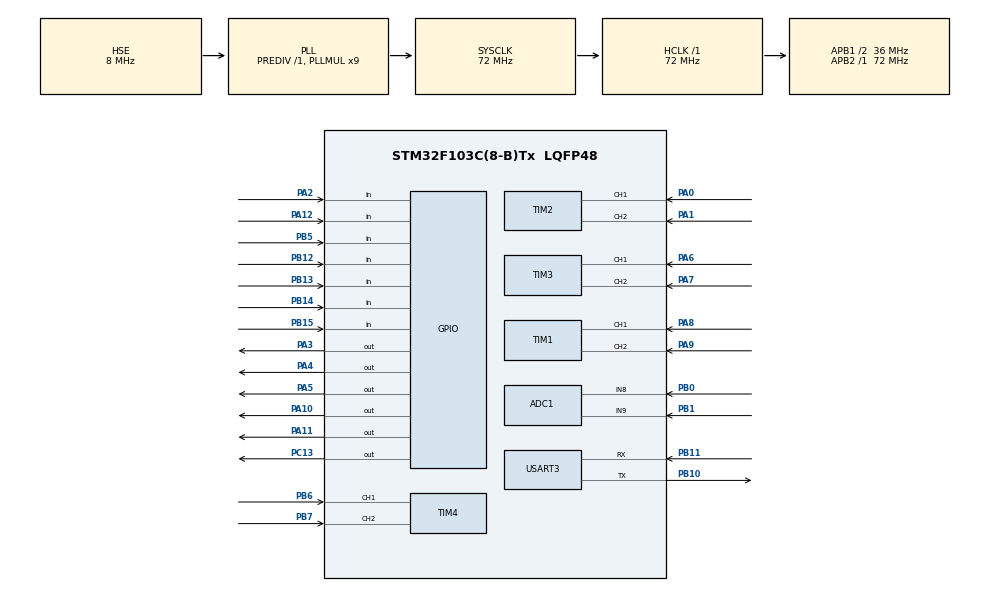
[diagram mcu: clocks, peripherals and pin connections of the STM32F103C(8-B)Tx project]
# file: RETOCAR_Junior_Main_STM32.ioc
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ADC1.Channel-2\#ChannelRegularConversion=ADC_CHANNEL_8
ADC1.NbrOfConversionFlag=1
ADC1.Rank-2\#ChannelRegularConversion=1
ADC1.SamplingTime-2\#ChannelRegularConversion=ADC_SAMPLETIME_239CYCLES_5
ADC1.master=1
Dma.Request0=USART3_RX
Dma.Request1=USART3_TX
Dma.USART3_RX.0.Direction=DMA_PERIPH_TO_MEMORY
Dma.USART3_RX.0.Instance=DMA1_Channel3
Dma.USART3_RX.0.MemDataAlignment=DMA_MDATAALIGN_BYTE
Dma.USART3_RX.0.MemInc=DMA_MINC_ENABLE
Dma.USART3_RX.0.Mode=DMA_CIRCULAR
Dma.USART3_RX.0.PeriphDataAlignment=DMA_PDATAALIGN_BYTE
Dma.USART3_RX.0.PeriphInc=DMA_PINC_DISABLE
Dma.USART3_RX.0.Priority=DMA_PRIORITY_LOW
Dma.USART3_TX.1.Direction=DMA_MEMORY_TO_PERIPH
Dma.USART3_TX.1.Instance=DMA1_Channel2
Dma.USART3_TX.1.MemDataAlignment=DMA_MDATAALIGN_BYTE
Dma.USART3_TX.1.MemInc=DMA_MINC_ENABLE
Dma.USART3_TX.1.Mode=DMA_NORMAL
Dma.USART3_TX.1.PeriphDataAlignment=DMA_PDATAALIGN_BYTE
Dma.USART3_TX.1.PeriphInc=DMA_PINC_DISABLE
Dma.USART3_TX.1.Priority=DMA_PRIORITY_LOW
Mcu.Family=STM32F1
Mcu.Name=STM32F103C(8-B)Tx
Mcu.Package=LQFP48
NVIC.DMA1_Channel2_IRQn=true\:0\:0\:false\:false\:true\:false\:true\:true
NVIC.DMA1_Channel3_IRQn=true\:0\:0\:false\:false\:true\:false\:true\:true
NVIC.PriorityGroup=NVIC_PRIORITYGROUP_4
NVIC.USART3_IRQn=true\:0\:0\:false\:false\:true\:true\:true\:true
PA0-WKUP.Signal=S_TIM2_CH1_ETR
PA1.Signal=S_TIM2_CH2
PA10.Signal=GPIO_Output
PA11.Signal=GPIO_Output
PA12.Signal=GPIO_Input
PA13.Mode=Serial_Wire
PA13.Signal=SYS_JTMS-SWDIO
PA14.Mode=Serial_Wire
PA14.Signal=SYS_JTCK-SWCLK
PA2.Signal=GPIO_Input
PA3.Signal=GPIO_Output
PA4.Signal=GPIO_Output
PA5.Signal=GPIO_Output
PA6.Signal=S_TIM3_CH1
PA7.Signal=S_TIM3_CH2
PA8.Signal=S_TIM1_CH1
PA9.Signal=S_TIM1_CH2
PB0.Signal=ADCx_IN8
PB1.Signal=ADCx_IN9
PB10.Mode=Asynchronous
PB10.Signal=USART3_TX
PB11.Mode=Asynchronous
PB11.Signal=USART3_RX
PB12.Signal=GPIO_Input
PB13.Signal=GPIO_Input
PB14.Signal=GPIO_Input
PB15.Signal=GPIO_Input
PB5.Signal=GPIO_Input
PB6.Signal=S_TIM4_CH1
PB7.Signal=S_TIM4_CH2
PC13-TAMPER-RTC.Signal=GPIO_Output
PD0-OSC_IN.Mode=HSE-External-Oscillator
PD0-OSC_IN.Signal=RCC_OSC_IN
PD1-OSC_OUT.Mode=HSE-External-Oscillator
PD1-OSC_OUT.Signal=RCC_OSC_OUT
ProjectManager.HeapSize=0x200
ProjectManager.StackSize=0x400
ProjectManager.TargetToolchain=STM32CubeIDE
RCC.AHBFreq_Value=72000000
RCC.APB1CLKDivider=RCC_HCLK_DIV2
RCC.APB1Freq_Value=36000000
RCC.APB1TimFreq_Value=72000000
RCC.APB2Freq_Value=72000000
RCC.APB2TimFreq_Value=72000000
RCC.EnbaleCSS=true
RCC.HCLKFreq_Value=72000000
RCC.PLLMUL=RCC_PLL_MUL9
RCC.PLLSourceVirtual=RCC_PLLSOURCE_HSE
RCC.SYSCLKFreq_VALUE=72000000
RCC.SYSCLKSource=RCC_SYSCLKSOURCE_PLLCLK
RCC.USBFreq_Value=72000000
SH.ADCx_IN8.0=ADC1_IN8,IN8
SH.ADCx_IN9.0=ADC1_IN9,IN9
SH.S_TIM1_CH1.0=TIM1_CH1,Encoder_Interface
SH.S_TIM1_CH2.0=TIM1_CH2,Encoder_Interface
SH.S_TIM2_CH1_ETR.0=TIM2_CH1,Encoder_Interface
SH.S_TIM2_CH2.0=TIM2_CH2,Encoder_Interface
SH.S_TIM3_CH1.0=TIM3_CH1,Encoder_Interface
SH.S_TIM3_CH2.0=TIM3_CH2,Encoder_Interface
SH.S_TIM4_CH1.0=TIM4_CH1,Encoder_Interface
SH.S_TIM4_CH2.0=TIM4_CH2,Encoder_Interface
TIM1.EncoderMode=TIM_ENCODERMODE_TI12
TIM1.IC1Filter=15
TIM1.IC2Filter=15
TIM2.EncoderMode=TIM_ENCODERMODE_TI12
TIM2.IC1Filter=15
TIM2.IC2Filter=15
TIM3.EncoderMode=TIM_ENCODERMODE_TI12
TIM3.IC1Filter=15
TIM3.IC2Filter=15
TIM4.EncoderMode=TIM_ENCODERMODE_TI12
TIM4.IC1Filter=15
TIM4.IC2Filter=15
USART3.VirtualMode=VM_ASYNC
board=custom

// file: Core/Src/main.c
/* USER CODE BEGIN Header */
/**
  ******************************************************************************
  * @file           : main.c
  * @brief          : Main program body
  ******************************************************************************
  * @attention
  *
  * Copyright (c) 2026 STMicroelectronics.
  * All rights reserved.
  *
  * This software is licensed under terms that can be found in the LICENSE file
  * in the root directory of this software component.
  * If no LICENSE file comes with this software, it is provided AS-IS.
  *
  ******************************************************************************
  */
/* USER CODE END Header */
#include "main.h"

/* USER CODE BEGIN Includes */
#include "../lib/Application.hpp"
/* USER CODE END Includes */

ADC_HandleTypeDef hadc1;

TIM_HandleTypeDef htim1;
TIM_HandleTypeDef htim2;
TIM_HandleTypeDef htim3;
TIM_HandleTypeDef htim4;

UART_HandleTypeDef huart3;
DMA_HandleTypeDef hdma_usart3_rx;
DMA_HandleTypeDef hdma_usart3_tx;

void SystemClock_Config(void);
static void MX_GPIO_Init(void);
static void MX_DMA_Init(void);
static void MX_TIM1_Init(void);
static void MX_TIM2_Init(void);
static void MX_TIM3_Init(void);
static void MX_TIM4_Init(void);
static void MX_USART3_UART_Init(void);
static void MX_ADC1_Init(void);

int main(void)
{

  /* MCU Configuration--------------------------------------------------------*/

  /* Reset of all peripherals, Initializes the Flash interface and the Systick. */
  HAL_Init();

  /* Configure the system clock */
  SystemClock_Config();

  /* Initialize all configured peripherals */
  MX_GPIO_Init();
  MX_DMA_Init();
  MX_TIM1_Init();
  MX_TIM2_Init();
  MX_TIM3_Init();
  MX_TIM4_Init();
  MX_USART3_UART_Init();
  MX_ADC1_Init();
  /* USER CODE BEGIN 2 */
  AppMain_Init();
  /* USER CODE END 2 */

  /* Infinite loop */
  while (1)
  {

    /* USER CODE BEGIN 3 */
    AppMain_Loop();
    HAL_Delay(10);
  }
  /* USER CODE END 3 */
}

void SystemClock_Config(void)
{
  RCC_OscInitTypeDef RCC_OscInitStruct = {0};
  RCC_ClkInitTypeDef RCC_ClkInitStruct = {0};
  RCC_PeriphCLKInitTypeDef PeriphClkInit = {0};

  /** Initializes the RCC Oscillators according to the specified parameters
  * in the RCC_OscInitTypeDef structure.
  */
  RCC_OscInitStruct.OscillatorType = RCC_OSCILLATORTYPE_HSE;
  RCC_OscInitStruct.HSEState = RCC_HSE_ON;
  RCC_OscInitStruct.HSEPredivValue = RCC_HSE_PREDIV_DIV1;
  RCC_OscInitStruct.HSIState = RCC_HSI_ON;
  RCC_OscInitStruct.PLL.PLLState = RCC_PLL_ON;
  RCC_OscInitStruct.PLL.PLLSource = RCC_PLLSOURCE_HSE;
  RCC_OscInitStruct.PLL.PLLMUL = RCC_PLL_MUL9;
  if (HAL_RCC_OscConfig(&RCC_OscInitStruct) != HAL_OK)
  {
    Error_Handler();
  }

  /** Initializes the CPU, AHB and APB buses clocks
  */
  RCC_ClkInitStruct.ClockType = RCC_CLOCKTYPE_HCLK|RCC_CLOCKTYPE_SYSCLK
                              |RCC_CLOCKTYPE_PCLK1|RCC_CLOCKTYPE_PCLK2;
  RCC_ClkInitStruct.SYSCLKSource = RCC_SYSCLKSOURCE_PLLCLK;
  RCC_ClkInitStruct.AHBCLKDivider = RCC_SYSCLK_DIV1;
  RCC_ClkInitStruct.APB1CLKDivider = RCC_HCLK_DIV2;
  RCC_ClkInitStruct.APB2CLKDivider = RCC_HCLK_DIV1;

  if (HAL_RCC_ClockConfig(&RCC_ClkInitStruct, FLASH_LATENCY_2) != HAL_OK)
  {
    Error_Handler();
  }
  PeriphClkInit.PeriphClockSelection = RCC_PERIPHCLK_ADC;
  PeriphClkInit.AdcClockSelection = RCC_ADCPCLK2_DIV2;
  if (HAL_RCCEx_PeriphCLKConfig(&PeriphClkInit) != HAL_OK)
  {
    Error_Handler();
  }

  /** Enables the Clock Security System
  */
  HAL_RCC_EnableCSS();
}

static void MX_ADC1_Init(void)
{

  ADC_ChannelConfTypeDef sConfig = {0};

  /** Common config
  */
  hadc1.Instance = ADC1;
  hadc1.Init.ScanConvMode = ADC_SCAN_DISABLE;
  hadc1.Init.ContinuousConvMode = DISABLE;
  hadc1.Init.DiscontinuousConvMode = DISABLE;
  hadc1.Init.ExternalTrigConv = ADC_SOFTWARE_START;
  hadc1.Init.DataAlign = ADC_DATAALIGN_RIGHT;
  hadc1.Init.NbrOfConversion = 1;
  if (HAL_ADC_Init(&hadc1) != HAL_OK)
  {
    Error_Handler();
  }

  /** Configure Regular Channel
  */
  sConfig.Channel = ADC_CHANNEL_8;
  sConfig.Rank = ADC_REGULAR_RANK_1;
  sConfig.SamplingTime = ADC_SAMPLETIME_239CYCLES_5;
  if (HAL_ADC_ConfigChannel(&hadc1, &sConfig) != HAL_OK)
  {
    Error_Handler();
  }

}

static void MX_TIM1_Init(void)
{

  TIM_Encoder_InitTypeDef sConfig = {0};
  TIM_MasterConfigTypeDef sMasterConfig = {0};

  htim1.Instance = TIM1;
  htim1.Init.Prescaler = 0;
  htim1.Init.CounterMode = TIM_COUNTERMODE_UP;
  htim1.Init.Period = 65535;
  htim1.Init.ClockDivision = TIM_CLOCKDIVISION_DIV1;
  htim1.Init.RepetitionCounter = 0;
  htim1.Init.AutoReloadPreload = TIM_AUTORELOAD_PRELOAD_DISABLE;
  sConfig.EncoderMode = TIM_ENCODERMODE_TI12;
  sConfig.IC1Polarity = TIM_ICPOLARITY_RISING;
  sConfig.IC1Selection = TIM_ICSELECTION_DIRECTTI;
  sConfig.IC1Prescaler = TIM_ICPSC_DIV1;
  sConfig.IC1Filter = 15;
  sConfig.IC2Polarity = TIM_ICPOLARITY_RISING;
  sConfig.IC2Selection = TIM_ICSELECTION_DIRECTTI;
  sConfig.IC2Prescaler = TIM_ICPSC_DIV1;
  sConfig.IC2Filter = 15;
  if (HAL_TIM_Encoder_Init(&htim1, &sConfig) != HAL_OK)
  {
    Error_Handler();
  }
  sMasterConfig.MasterOutputTrigger = TIM_TRGO_RESET;
  sMasterConfig.MasterSlaveMode = TIM_MASTERSLAVEMODE_DISABLE;
  if (HAL_TIMEx_MasterConfigSynchronization(&htim1, &sMasterConfig) != HAL_OK)
  {
    Error_Handler();
  }

}

static void MX_TIM2_Init(void)
{

  TIM_Encoder_InitTypeDef sConfig = {0};
  TIM_MasterConfigTypeDef sMasterConfig = {0};

  htim2.Instance = TIM2;
  htim2.Init.Prescaler = 0;
  htim2.Init.CounterMode = TIM_COUNTERMODE_UP;
  htim2.Init.Period = 65535;
  htim2.Init.ClockDivision = TIM_CLOCKDIVISION_DIV1;
  htim2.Init.AutoReloadPreload = TIM_AUTORELOAD_PRELOAD_DISABLE;
  sConfig.EncoderMode = TIM_ENCODERMODE_TI12;
  sConfig.IC1Polarity = TIM_ICPOLARITY_RISING;
  sConfig.IC1Selection = TIM_ICSELECTION_DIRECTTI;
  sConfig.IC1Prescaler = TIM_ICPSC_DIV1;
  sConfig.IC1Filter = 15;
  sConfig.IC2Polarity = TIM_ICPOLARITY_RISING;
  sConfig.IC2Selection = TIM_ICSELECTION_DIRECTTI;
  sConfig.IC2Prescaler = TIM_ICPSC_DIV1;
  sConfig.IC2Filter = 15;
  if (HAL_TIM_Encoder_Init(&htim2, &sConfig) != HAL_OK)
  {
    Error_Handler();
  }
  sMasterConfig.MasterOutputTrigger = TIM_TRGO_RESET;
  sMasterConfig.MasterSlaveMode = TIM_MASTERSLAVEMODE_DISABLE;
  if (HAL_TIMEx_MasterConfigSynchronization(&htim2, &sMasterConfig) != HAL_OK)
  {
    Error_Handler();
  }

}

static void MX_TIM3_Init(void)
{

  TIM_Encoder_InitTypeDef sConfig = {0};
  TIM_MasterConfigTypeDef sMasterConfig = {0};

  htim3.Instance = TIM3;
  htim3.Init.Prescaler = 0;
  htim3.Init.CounterMode = TIM_COUNTERMODE_UP;
  htim3.Init.Period = 65535;
  htim3.Init.ClockDivision = TIM_CLOCKDIVISION_DIV1;
  htim3.Init.AutoReloadPreload = TIM_AUTORELOAD_PRELOAD_DISABLE;
  sConfig.EncoderMode = TIM_ENCODERMODE_TI12;
  sConfig.IC1Polarity = TIM_ICPOLARITY_RISING;
  sConfig.IC1Selection = TIM_ICSELECTION_DIRECTTI;
  sConfig.IC1Prescaler = TIM_ICPSC_DIV1;
  sConfig.IC1Filter = 15;
  sConfig.IC2Polarity = TIM_ICPOLARITY_RISING;
  sConfig.IC2Selection = TIM_ICSELECTION_DIRECTTI;
  sConfig.IC2Prescaler = TIM_ICPSC_DIV1;
  sConfig.IC2Filter = 15;
  if (HAL_TIM_Encoder_Init(&htim3, &sConfig) != HAL_OK)
  {
    Error_Handler();
  }
  sMasterConfig.MasterOutputTrigger = TIM_TRGO_RESET;
  sMasterConfig.MasterSlaveMode = TIM_MASTERSLAVEMODE_DISABLE;
  if (HAL_TIMEx_MasterConfigSynchronization(&htim3, &sMasterConfig) != HAL_OK)
  {
    Error_Handler();
  }

}

static void MX_TIM4_Init(void)
{

  TIM_Encoder_InitTypeDef sConfig = {0};
  TIM_MasterConfigTypeDef sMasterConfig = {0};

  htim4.Instance = TIM4;
  htim4.Init.Prescaler = 0;
  htim4.Init.CounterMode = TIM_COUNTERMODE_UP;
  htim4.Init.Period = 65535;
  htim4.Init.ClockDivision = TIM_CLOCKDIVISION_DIV1;
  htim4.Init.AutoReloadPreload = TIM_AUTORELOAD_PRELOAD_DISABLE;
  sConfig.EncoderMode = TIM_ENCODERMODE_TI12;
  sConfig.IC1Polarity = TIM_ICPOLARITY_RISING;
  sConfig.IC1Selection = TIM_ICSELECTION_DIRECTTI;
  sConfig.IC1Prescaler = TIM_ICPSC_DIV1;
  sConfig.IC1Filter = 15;
  sConfig.IC2Polarity = TIM_ICPOLARITY_RISING;
  sConfig.IC2Selection = TIM_ICSELECTION_DIRECTTI;
  sConfig.IC2Prescaler = TIM_ICPSC_DIV1;
  sConfig.IC2Filter = 15;
  if (HAL_TIM_Encoder_Init(&htim4, &sConfig) != HAL_OK)
  {
    Error_Handler();
  }
  sMasterConfig.MasterOutputTrigger = TIM_TRGO_RESET;
  sMasterConfig.MasterSlaveMode = TIM_MASTERSLAVEMODE_DISABLE;
  if (HAL_TIMEx_MasterConfigSynchronization(&htim4, &sMasterConfig) != HAL_OK)
  {
    Error_Handler();
  }

}

static void MX_USART3_UART_Init(void)
{

  huart3.Instance = USART3;
  huart3.Init.BaudRate = 115200;
  huart3.Init.WordLength = UART_WORDLENGTH_8B;
  huart3.Init.StopBits = UART_STOPBITS_1;
  huart3.Init.Parity = UART_PARITY_NONE;
  huart3.Init.Mode = UART_MODE_TX_RX;
  huart3.Init.HwFlowCtl = UART_HWCONTROL_NONE;
  huart3.Init.OverSampling = UART_OVERSAMPLING_16;
  if (HAL_UART_Init(&huart3) != HAL_OK)
  {
    Error_Handler();
  }

}

static void MX_DMA_Init(void)
{

  /* DMA controller clock enable */
  __HAL_RCC_DMA1_CLK_ENABLE();

  /* DMA interrupt init */
  /* DMA1_Channel2_IRQn interrupt configuration */
  HAL_NVIC_SetPriority(DMA1_Channel2_IRQn, 0, 0);
  HAL_NVIC_EnableIRQ(DMA1_Channel2_IRQn);
  /* DMA1_Channel3_IRQn interrupt configuration */
  HAL_NVIC_SetPriority(DMA1_Channel3_IRQn, 0, 0);
  HAL_NVIC_EnableIRQ(DMA1_Channel3_IRQn);

}

static void MX_GPIO_Init(void)
{
  GPIO_InitTypeDef GPIO_InitStruct = {0};

  /* GPIO Ports Clock Enable */
  __HAL_RCC_GPIOC_CLK_ENABLE();
  __HAL_RCC_GPIOD_CLK_ENABLE();
  __HAL_RCC_GPIOA_CLK_ENABLE();
  __HAL_RCC_GPIOB_CLK_ENABLE();

  /*Configure GPIO pin Output Level */
  HAL_GPIO_WritePin(GPIOC, GPIO_PIN_13, GPIO_PIN_RESET);

  /*Configure GPIO pin Output Level */
  HAL_GPIO_WritePin(GPIOA, GPIO_PIN_3|GPIO_PIN_4|GPIO_PIN_5|GPIO_PIN_10
                          |GPIO_PIN_11, GPIO_PIN_RESET);

  /*Configure GPIO pin : PC13 */
  GPIO_InitStruct.Pin = GPIO_PIN_13;
  GPIO_InitStruct.Mode = GPIO_MODE_OUTPUT_PP;
  GPIO_InitStruct.Pull = GPIO_NOPULL;
  GPIO_InitStruct.Speed = GPIO_SPEED_FREQ_LOW;
  HAL_GPIO_Init(GPIOC, &GPIO_InitStruct);

  /*Configure GPIO pins : PA2 PA12 */
  GPIO_InitStruct.Pin = GPIO_PIN_2|GPIO_PIN_12;
  GPIO_InitStruct.Mode = GPIO_MODE_INPUT;
  GPIO_InitStruct.Pull = GPIO_NOPULL;
  HAL_GPIO_Init(GPIOA, &GPIO_InitStruct);

  /*Configure GPIO pins : PA3 PA4 PA5 PA10
                           PA11 */
  GPIO_InitStruct.Pin = GPIO_PIN_3|GPIO_PIN_4|GPIO_PIN_5|GPIO_PIN_10
                          |GPIO_PIN_11;
  GPIO_InitStruct.Mode = GPIO_MODE_OUTPUT_PP;
  GPIO_InitStruct.Pull = GPIO_NOPULL;
  GPIO_InitStruct.Speed = GPIO_SPEED_FREQ_LOW;
  HAL_GPIO_Init(GPIOA, &GPIO_InitStruct);

  /*Configure GPIO pins : PB12 PB13 PB14 PB15
                           PB5 */
  GPIO_InitStruct.Pin = GPIO_PIN_12|GPIO_PIN_13|GPIO_PIN_14|GPIO_PIN_15
                          |GPIO_PIN_5;
  GPIO_InitStruct.Mode = GPIO_MODE_INPUT;
  GPIO_InitStruct.Pull = GPIO_NOPULL;
  HAL_GPIO_Init(GPIOB, &GPIO_InitStruct);

}

void Error_Handler(void)
{
  __disable_irq();
  while (1)
  {
  }
}
